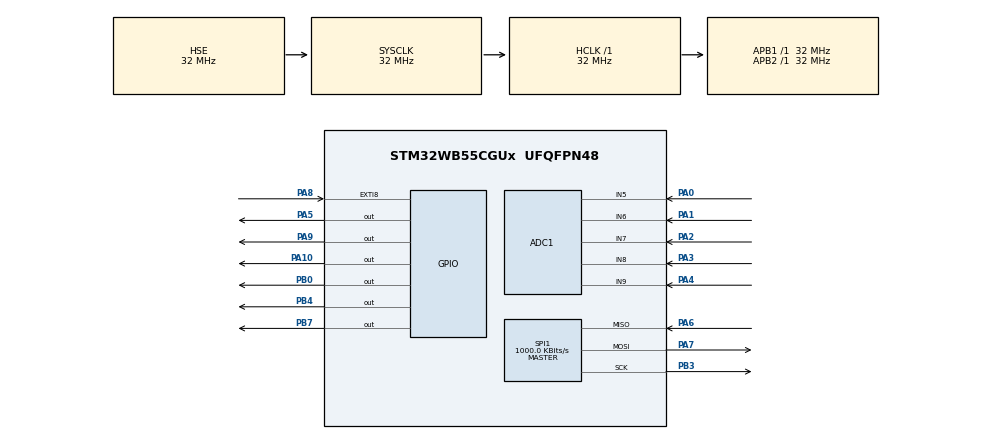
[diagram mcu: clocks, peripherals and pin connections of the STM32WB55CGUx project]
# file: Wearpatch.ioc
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ADC1.Channel-0\#ChannelRegularConversion=ADC_CHANNEL_5
ADC1.Channel-5\#ChannelRegularConversion=ADC_CHANNEL_6
ADC1.Channel-6\#ChannelRegularConversion=ADC_CHANNEL_7
ADC1.Channel-7\#ChannelRegularConversion=ADC_CHANNEL_8
ADC1.Channel-8\#ChannelRegularConversion=ADC_CHANNEL_9
ADC1.ClockPrescaler=ADC_CLOCK_ASYNC_DIV12
ADC1.NbrOfConversion=5
ADC1.NbrOfConversionFlag=1
ADC1.OffsetNumber-5\#ChannelRegularConversion=ADC_OFFSET_NONE
ADC1.OffsetNumber-6\#ChannelRegularConversion=ADC_OFFSET_NONE
ADC1.OffsetNumber-7\#ChannelRegularConversion=ADC_OFFSET_NONE
ADC1.OffsetNumber-8\#ChannelRegularConversion=ADC_OFFSET_NONE
ADC1.Rank-5\#ChannelRegularConversion=2
ADC1.Rank-6\#ChannelRegularConversion=3
ADC1.Rank-7\#ChannelRegularConversion=4
ADC1.Rank-8\#ChannelRegularConversion=5
ADC1.SamplingTime-0\#ChannelRegularConversion=ADC_SAMPLETIME_12CYCLES_5
ADC1.SamplingTime-5\#ChannelRegularConversion=ADC_SAMPLETIME_12CYCLES_5
ADC1.SamplingTime-6\#ChannelRegularConversion=ADC_SAMPLETIME_12CYCLES_5
ADC1.SamplingTime-7\#ChannelRegularConversion=ADC_SAMPLETIME_12CYCLES_5
ADC1.SamplingTime-8\#ChannelRegularConversion=ADC_SAMPLETIME_12CYCLES_5
ADC1.master=1
Dma.ADC1.0.Direction=DMA_PERIPH_TO_MEMORY
Dma.ADC1.0.EventEnable=DISABLE
Dma.ADC1.0.Instance=DMA1_Channel1
Dma.ADC1.0.MemDataAlignment=DMA_MDATAALIGN_HALFWORD
Dma.ADC1.0.MemInc=DMA_MINC_ENABLE
Dma.ADC1.0.Mode=DMA_NORMAL
Dma.ADC1.0.PeriphDataAlignment=DMA_PDATAALIGN_HALFWORD
Dma.ADC1.0.PeriphInc=DMA_PINC_DISABLE
Dma.ADC1.0.Polarity=HAL_DMAMUX_REQ_GEN_RISING
Dma.ADC1.0.Priority=DMA_PRIORITY_LOW
Dma.ADC1.0.RequestNumber=1
Dma.ADC1.0.SignalID=NONE
Dma.ADC1.0.SyncEnable=DISABLE
Dma.ADC1.0.SyncPolarity=HAL_DMAMUX_SYNC_NO_EVENT
Dma.ADC1.0.SyncRequestNumber=1
Dma.ADC1.0.SyncSignalID=NONE
Dma.Request0=ADC1
Mcu.Family=STM32WB
Mcu.Name=STM32WB55CGUx
Mcu.Package=UFQFPN48
NVIC.ADC1_IRQn=true\:15\:0\:true\:false\:true\:true\:true\:true
NVIC.DMA1_Channel1_IRQn=true\:0\:0\:false\:false\:true\:false\:true\:true
NVIC.EXTI9_5_IRQn=true\:15\:0\:true\:false\:true\:true\:true\:true
NVIC.HSEM_IRQn=true\:0\:0\:false\:false\:true\:false\:true\:true
NVIC.IPCC_C1_RX_IRQn=true\:0\:0\:false\:false\:true\:true\:true\:true
NVIC.IPCC_C1_TX_IRQn=true\:0\:0\:false\:false\:true\:true\:true\:true
NVIC.PriorityGroup=NVIC_PRIORITYGROUP_4
NVIC.RTC_WKUP_IRQn=true\:0\:0\:false\:false\:true\:true\:true\:true
NVIC.SPI1_IRQn=true\:15\:0\:true\:false\:true\:true\:true\:true
OSC_IN.Mode=HSE-External-Oscillator
OSC_IN.Signal=RCC_OSC_IN
OSC_OUT.Mode=HSE-External-Oscillator
OSC_OUT.Signal=RCC_OSC_OUT
PA0.Signal=ADCx_IN5
PA1.Signal=ADCx_IN6
PA10.Signal=GPIO_Output
PA13.Mode=Serial_Wire
PA13.Signal=SYS_JTMS-SWDIO
PA14.Mode=Serial_Wire
PA14.Signal=SYS_JTCK-SWCLK
PA2.Signal=ADCx_IN7
PA3.Signal=ADCx_IN8
PA4.Signal=ADCx_IN9
PA5.Signal=GPIO_Output
PA6.Mode=Full_Duplex_Master
PA6.Signal=SPI1_MISO
PA7.Mode=Full_Duplex_Master
PA7.Signal=SPI1_MOSI
PA8.GPIO_ModeDefaultEXTI=GPIO_MODE_IT_FALLING
PA8.GPIO_PuPd=GPIO_PULLUP
PA8.Signal=GPXTI8
PA9.Signal=GPIO_Output
PB0.Signal=GPIO_Output
PB3.Mode=Full_Duplex_Master
PB3.Signal=SPI1_SCK
PB4.Signal=GPIO_Output
PB7.Signal=GPIO_Output
PB8.Signal=S_TIM16_CH1
PC14-OSC32_IN.Mode=LSE-External-Oscillator
PC14-OSC32_IN.Signal=RCC_OSC32_IN
PC15-OSC32_OUT.Mode=LSE-External-Oscillator
PC15-OSC32_OUT.Signal=RCC_OSC32_OUT
ProjectManager.HeapSize=0x200
ProjectManager.StackSize=0x400
ProjectManager.TargetToolchain=MDK-ARM V5.32
RCC.ADCFreq_Value=48000000
RCC.AHBFreq_Value=32000000
RCC.APB1Freq_Value=32000000
RCC.APB1TimFreq_Value=32000000
RCC.APB2Freq_Value=32000000
RCC.APB2TimFreq_Value=32000000
RCC.APB3Freq_Value=16000000
RCC.CortexFreq_Value=32000000
RCC.HCLKFreq_Value=32000000
RCC.HSE_VALUE=32000000
RCC.HSI48_VALUE=48000000
RCC.HSI_VALUE=16000000
RCC.PLLSAI1N=24
RCC.RFWKPClockSelection=RCC_RFWKPCLKSOURCE_LSE
RCC.RTCClockSelection=RCC_RTCCLKSOURCE_LSE
RCC.SMPSCLockSelection=RCC_SMPSCLKSOURCE_HSE
RCC.SMPSDivider=4
RCC.SYSCLKFreq_VALUE=32000000
RCC.SYSCLKSource=RCC_SYSCLKSOURCE_HSE
RCC.USBFreq_Value=48000000
RCC.VCOOutputFreq_Value=32000000
RF1.Mode=RF1_Activate
RF1.Signal=RF_RF1
SH.ADCx_IN5.0=ADC1_IN5,IN5-Single-Ended
SH.ADCx_IN6.0=ADC1_IN6,IN6-Single-Ended
SH.ADCx_IN7.0=ADC1_IN7,IN7-Single-Ended
SH.ADCx_IN8.0=ADC1_IN8,IN8-Single-Ended
SH.ADCx_IN9.0=ADC1_IN9,IN9-Single-Ended
SH.S_TIM16_CH1.0=TIM16_CH1
SPI1.BaudRatePrescaler=SPI_BAUDRATEPRESCALER_32
SPI1.CLKPhase=SPI_PHASE_2EDGE
SPI1.CLKPolarity=SPI_POLARITY_HIGH
SPI1.CalculateBaudRate=1000.0 KBits/s
SPI1.DataSize=SPI_DATASIZE_8BIT
SPI1.Direction=SPI_DIRECTION_2LINES
SPI1.Mode=SPI_MODE_MASTER
SPI1.VirtualType=VM_MASTER
STM32_WPAN.CFG_DEBUGGER_SUPPORTED=0
STM32_WPAN.CFG_LPM_SUPPORTED=1
STM32_WPAN.LOCAL_NAME=Wearpat
STM32_WPAN.LOCAL_NAME_FORMATTED=,'W','e','a','r','p','a','t'
VP_HSEM_VS_HSEM.Mode=HSEM_Activate
VP_IPCC_VS_IPCC.Mode=IPCC_Activate
VP_MEMORYMAP_VS_MEMORYMAP.Mode=CurAppReg
VP_RTC_VS_RTC_Activate.Mode=RTC_Enabled
VP_RTC_VS_RTC_WakeUp_intern.Mode=WakeUp
VP_SEQUENCER_VS_SEQUENCER.Mode=SEQUENCER_Enabled
VP_STM32_WPAN_VS_BLE_HOST.Mode=STM32_WPAN_Enabled
VP_TINY_LPM_VS_TINY_LPM.Mode=TINY_LPM_Enabled
board=custom

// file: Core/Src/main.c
/* USER CODE BEGIN Header */
/**
  ******************************************************************************
  * @file           : main.c
  * @brief          : Main program body
  ******************************************************************************
  * @attention
  *
  * Copyright (c) 2024 STMicroelectronics.
  * All rights reserved.
  *
  * This software is licensed under terms that can be found in the LICENSE file
  * in the root directory of this software component.
  * If no LICENSE file comes with this software, it is provided AS-IS.
  *
  ******************************************************************************
  */
/* USER CODE END Header */
#include "main.h"
#include "adc.h"
#include "dma.h"
#include "ipcc.h"
#include "memorymap.h"
#include "rf.h"
#include "rtc.h"
#include "spi.h"
#include "gpio.h"

void SystemClock_Config(void);
void PeriphCommonClock_Config(void);

int main(void)
{

  /* MCU Configuration--------------------------------------------------------*/

  /* Reset of all peripherals, Initializes the Flash interface and the Systick. */
  HAL_Init();
  /* Config code for STM32_WPAN (HSE Tuning must be done before system clock configuration) */
  MX_APPE_Config();

  /* Configure the system clock */
  SystemClock_Config();

/* Configure the peripherals common clocks */
  PeriphCommonClock_Config();

  /* IPCC initialisation */
  MX_IPCC_Init();

  /* Initialize all configured peripherals */
  MX_GPIO_Init();
  MX_DMA_Init();
  MX_RTC_Init();
  MX_SPI1_Init();
  MX_ADC1_Init();
  MX_RF_Init();
  /* USER CODE BEGIN 2 */

//MAX5531_SetVoltage(500.0f);

  /* USER CODE END 2 */

  /* Init code for STM32_WPAN */
  MX_APPE_Init();

  /* Infinite loop */
  while (1)
  {
    MX_APPE_Process();

  }
}

void SystemClock_Config(void)
{
  RCC_OscInitTypeDef RCC_OscInitStruct = {0};
  RCC_ClkInitTypeDef RCC_ClkInitStruct = {0};

  /** Macro to configure the PLL multiplication factor
  */
  __HAL_RCC_PLL_PLLM_CONFIG(RCC_PLLM_DIV1);

  /** Macro to configure the PLL clock source
  */
  __HAL_RCC_PLL_PLLSOURCE_CONFIG(RCC_PLLSOURCE_MSI);

  /** Configure LSE Drive Capability
  */
  HAL_PWR_EnableBkUpAccess();
  __HAL_RCC_LSEDRIVE_CONFIG(RCC_LSEDRIVE_MEDIUMHIGH);

  /** Configure the main internal regulator output voltage
  */
  __HAL_PWR_VOLTAGESCALING_CONFIG(PWR_REGULATOR_VOLTAGE_SCALE1);

  /** Initializes the RCC Oscillators according to the specified parameters
  * in the RCC_OscInitTypeDef structure.
  */
  RCC_OscInitStruct.OscillatorType = RCC_OSCILLATORTYPE_HSI|RCC_OSCILLATORTYPE_HSE
                              |RCC_OSCILLATORTYPE_LSE|RCC_OSCILLATORTYPE_MSI;
  RCC_OscInitStruct.HSEState = RCC_HSE_ON;
  RCC_OscInitStruct.LSEState = RCC_LSE_ON;
  RCC_OscInitStruct.HSIState = RCC_HSI_ON;
  RCC_OscInitStruct.MSIState = RCC_MSI_ON;
  RCC_OscInitStruct.HSICalibrationValue = RCC_HSICALIBRATION_DEFAULT;
  RCC_OscInitStruct.MSICalibrationValue = RCC_MSICALIBRATION_DEFAULT;
  RCC_OscInitStruct.MSIClockRange = RCC_MSIRANGE_6;
  RCC_OscInitStruct.PLL.PLLState = RCC_PLL_NONE;
  if (HAL_RCC_OscConfig(&RCC_OscInitStruct) != HAL_OK)
  {
    Error_Handler();
  }

  /** Configure the SYSCLKSource, HCLK, PCLK1 and PCLK2 clocks dividers
  */
  RCC_ClkInitStruct.ClockType = RCC_CLOCKTYPE_HCLK4|RCC_CLOCKTYPE_HCLK2
                              |RCC_CLOCKTYPE_HCLK|RCC_CLOCKTYPE_SYSCLK
                              |RCC_CLOCKTYPE_PCLK1|RCC_CLOCKTYPE_PCLK2;
  RCC_ClkInitStruct.SYSCLKSource = RCC_SYSCLKSOURCE_HSE;
  RCC_ClkInitStruct.AHBCLKDivider = RCC_SYSCLK_DIV1;
  RCC_ClkInitStruct.APB1CLKDivider = RCC_HCLK_DIV1;
  RCC_ClkInitStruct.APB2CLKDivider = RCC_HCLK_DIV1;
  RCC_ClkInitStruct.AHBCLK2Divider = RCC_SYSCLK_DIV1;
  RCC_ClkInitStruct.AHBCLK4Divider = RCC_SYSCLK_DIV1;

  if (HAL_RCC_ClockConfig(&RCC_ClkInitStruct, FLASH_LATENCY_1) != HAL_OK)
  {
    Error_Handler();
  }
}

void PeriphCommonClock_Config(void)
{
  RCC_PeriphCLKInitTypeDef PeriphClkInitStruct = {0};

  /** Initializes the peripherals clock
  */
  PeriphClkInitStruct.PeriphClockSelection = RCC_PERIPHCLK_SMPS|RCC_PERIPHCLK_RFWAKEUP;
  PeriphClkInitStruct.RFWakeUpClockSelection = RCC_RFWKPCLKSOURCE_LSE;
  PeriphClkInitStruct.SmpsClockSelection = RCC_SMPSCLKSOURCE_HSE;
  PeriphClkInitStruct.SmpsDivSelection = RCC_SMPSCLKDIV_RANGE1;

  if (HAL_RCCEx_PeriphCLKConfig(&PeriphClkInitStruct) != HAL_OK)
  {
    Error_Handler();
  }
}

void Error_Handler(void)
{
  __disable_irq();
  while (1)
  {
  }
}
